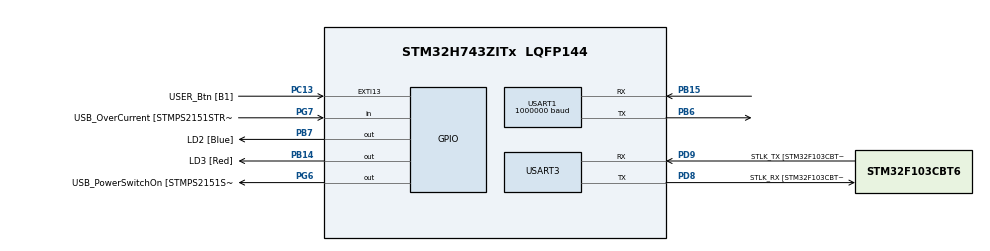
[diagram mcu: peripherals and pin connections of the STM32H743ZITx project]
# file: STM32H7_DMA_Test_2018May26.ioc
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Dma.Request0=USART1_TX
Dma.Request1=USART3_TX
Dma.USART1_TX.0.Direction=DMA_MEMORY_TO_PERIPH
Dma.USART1_TX.0.EventEnable=DISABLE
Dma.USART1_TX.0.FIFOMode=DMA_FIFOMODE_DISABLE
Dma.USART1_TX.0.Instance=DMA1_Stream0
Dma.USART1_TX.0.MemDataAlignment=DMA_MDATAALIGN_BYTE
Dma.USART1_TX.0.MemInc=DMA_MINC_ENABLE
Dma.USART1_TX.0.Mode=DMA_NORMAL
Dma.USART1_TX.0.PeriphDataAlignment=DMA_PDATAALIGN_BYTE
Dma.USART1_TX.0.PeriphInc=DMA_PINC_DISABLE
Dma.USART1_TX.0.Polarity=HAL_DMAMUX_REQ_GEN_RISING
Dma.USART1_TX.0.Priority=DMA_PRIORITY_LOW
Dma.USART1_TX.0.RequestNumber=1
Dma.USART1_TX.0.SyncEnable=DISABLE
Dma.USART1_TX.0.SyncPolarity=HAL_DMAMUX_SYNC_NO_EVENT
Dma.USART1_TX.0.SyncRequestNumber=1
Dma.USART3_TX.1.Direction=DMA_MEMORY_TO_PERIPH
Dma.USART3_TX.1.EventEnable=DISABLE
Dma.USART3_TX.1.FIFOMode=DMA_FIFOMODE_DISABLE
Dma.USART3_TX.1.Instance=DMA2_Stream1
Dma.USART3_TX.1.MemDataAlignment=DMA_MDATAALIGN_BYTE
Dma.USART3_TX.1.MemInc=DMA_MINC_ENABLE
Dma.USART3_TX.1.Mode=DMA_NORMAL
Dma.USART3_TX.1.PeriphDataAlignment=DMA_PDATAALIGN_BYTE
Dma.USART3_TX.1.PeriphInc=DMA_PINC_DISABLE
Dma.USART3_TX.1.Polarity=HAL_DMAMUX_REQ_GEN_RISING
Dma.USART3_TX.1.Priority=DMA_PRIORITY_LOW
Dma.USART3_TX.1.RequestNumber=1
Dma.USART3_TX.1.SyncEnable=DISABLE
Dma.USART3_TX.1.SyncPolarity=HAL_DMAMUX_SYNC_NO_EVENT
Dma.USART3_TX.1.SyncRequestNumber=1
FREERTOS.BinarySemaphores01=semTx,Static,semTxControlBlock
FREERTOS.MEMORY_ALLOCATION=2
FREERTOS.Tasks01=defaultTask,0,128,StartDefaultTask,Default,NULL,Dynamic,NULL,NULL;txTask,1,128,StartTxTask,Default,NULL,Static,txTaskBuffer,txTaskControlBlock
Mcu.Family=STM32H7
Mcu.Name=STM32H743ZITx
Mcu.Package=LQFP144
NVIC.DMA1_Stream0_IRQn=true\:5\:0\:false\:false\:true\:true\:false
NVIC.DMA2_Stream1_IRQn=true\:0\:0\:false\:false\:true\:false\:false
NVIC.PriorityGroup=NVIC_PRIORITYGROUP_4
NVIC.TIM1_UP_IRQn=true\:0\:0\:false\:false\:true\:false\:false
NVIC.TimeBase=TIM1_UP_IRQn
NVIC.TimeBaseIP=TIM1
NVIC.USART1_IRQn=true\:5\:0\:false\:false\:true\:true\:true
NVIC.USART3_IRQn=true\:5\:0\:false\:false\:true\:true\:true
PA1.GPIO_Label=RMII_REF_CLK
PA1.Signal=ETH_REF_CLK
PA10.GPIO_Label=USB_ID
PA10.Signal=USB_OTG_FS_ID
PA11.GPIO_Label=USB_DM
PA11.Signal=USB_OTG_FS_DM
PA12.GPIO_Label=USB_DP
PA12.Signal=USB_OTG_FS_DP
PA13.GPIO_Label=TMS
PA13.Mode=Serial_Wire
PA13.Signal=SYS_JTMS-SWDIO
PA14.GPIO_Label=TCK
PA14.Mode=Serial_Wire
PA14.Signal=SYS_JTCK-SWCLK
PA2.GPIO_Label=RMII_MDIO
PA2.Signal=ETH_MDIO
PA7.GPIO_Label=RMII_CRS_DV
PA7.Signal=ETH_CRS_DV
PA8.GPIO_Label=USB_SOF [TP1]
PA8.Signal=USB_OTG_FS_SOF
PA9.GPIO_Label=USB_VBUS
PA9.Signal=USB_OTG_FS_VBUS
PB13.GPIO_Label=RMII_TXD1
PB13.Signal=ETH_TXD1
PB14.GPIO_Label=LD3 [Red]
PB14.Signal=GPIO_Output
PB15.Mode=Asynchronous
PB15.Signal=USART1_RX
PB3.GPIO_Label=SWO
PB3.Signal=SYS_JTDO-SWO
PB6.Mode=Asynchronous
PB6.Signal=USART1_TX
PB7.GPIO_Label=LD2 [Blue]
PB7.Signal=GPIO_Output
PC1.GPIO_Label=RMII_MDC
PC1.Signal=ETH_MDC
PC13.GPIO_Label=USER_Btn [B1]
PC13.Signal=GPXTI13
PC14-OSC32_IN.Mode=LSE-External-Oscillator
PC14-OSC32_IN.Signal=RCC_OSC32_IN
PC15-OSC32_OUT.Mode=LSE-External-Oscillator
PC15-OSC32_OUT.Signal=RCC_OSC32_OUT
PC4.GPIO_Label=RMII_RXD0
PC4.Signal=ETH_RXD0
PC5.GPIO_Label=RMII_RXD1
PC5.Signal=ETH_RXD1
PD8.GPIO_Label=STLK_RX [STM32F103CBT6_PA3]
PD8.Mode=Asynchronous
PD8.Signal=USART3_TX
PD9.GPIO_Label=STLK_TX [STM32F103CBT6_PA2]
PD9.Mode=Asynchronous
PD9.Signal=USART3_RX
PG11.GPIO_Label=RMII_TX_EN
PG11.Signal=ETH_TX_EN
PG13.GPIO_Label=RMII_TXD0
PG13.Signal=ETH_TXD0
PG6.GPIO_Label=USB_PowerSwitchOn [STMPS2151STR_EN]
PG6.Signal=GPIO_Output
PG7.GPIO_Label=USB_OverCurrent [STMPS2151STR_FAULT]
PG7.Signal=GPIO_Input
PH0-OSC_IN.GPIO_Label=MCO
PH0-OSC_IN.Mode=HSE-External-Clock-Source
PH0-OSC_IN.Signal=RCC_OSC_IN
PH1-OSC_OUT.Mode=HSE-External-Clock-Source
PH1-OSC_OUT.Signal=RCC_OSC_OUT
ProjectManager.HeapSize=0x200
ProjectManager.StackSize=0x400
ProjectManager.TargetToolchain=SW4STM32
RCC.48MHZClocksFreq_Value=24000000
RCC.ADCFreq_Value=16125000
RCC.AHBFreq_Value=216000000
RCC.APB1CLKDivider=RCC_HCLK_DIV4
RCC.APB1Freq_Value=96000000
RCC.APB1TimFreq_Value=108000000
RCC.APB2CLKDivider=RCC_HCLK_DIV2
RCC.APB2Freq_Value=96000000
RCC.APB2TimFreq_Value=216000000
RCC.APB3Freq_Value=96000000
RCC.APB4Freq_Value=96000000
RCC.CortexFreq_Value=96000000
RCC.DIVM1=1
RCC.DIVN1=24
RCC.DIVQ1=4
RCC.HCLKFreq_Value=96000000
RCC.HSE_VALUE=8000000
RCC.HSI_VALUE=64000000
RCC.PLLM=25
RCC.PLLMUL=RCC_PLL_MUL9
RCC.PLLN=432
RCC.PLLQ=9
RCC.PLLSourceVirtual=RCC_PLLSOURCE_HSE
RCC.PRESCALERUSB=RCC_USBCLKSOURCE_PLL_DIV1_5
RCC.SYSCLKFreq_VALUE=96000000
RCC.SYSCLKSource=RCC_SYSCLKSOURCE_PLLCLK
RCC.SYSCLKSourceVirtual=RCC_SYSCLKSOURCE_PLLCLK
RCC.USBFreq_Value=48000000
RCC.VCOOutputFreq_Value=432000000
USART1.BaudRate=1000000
USART1.VirtualMode-Asynchronous=VM_ASYNC
USART1.WordLength=WORDLENGTH_8B
USART3.FIFOMode=FIFOMODE_DISABLE
USART3.RXFIFOThreshold=RXFIFO_THRESHOLD_1QUARTERFULL
USART3.TXFIFOThreshold=TXFIFO_THRESHOLD_1QUARTERFULL
USART3.VirtualMode-Asynchronous=VM_ASYNC
USART3.WordLength=WORDLENGTH_8B
VP_FREERTOS_VS_ENABLE.Mode=Enabled
VP_SYS_VS_tim1.Mode=TIM1
board=NUCLEO-H743ZI

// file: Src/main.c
/**
  ******************************************************************************
  * @file           : main.c
  * @brief          : Main program body
  ******************************************************************************
  * This notice applies to any and all portions of this file
  * that are not between comment pairs USER CODE BEGIN and
  * USER CODE END. Other portions of this file, whether
  * inserted by the user or by software development tools
  * are owned by their respective copyright owners.
  *
  * Copyright (c) 2018 STMicroelectronics International N.V.
  * All rights reserved.
  *
  * Redistribution and use in source and binary forms, with or without
  * modification, are permitted, provided that the following conditions are met:
  *
  * 1. Redistribution of source code must retain the above copyright notice,
  *    this list of conditions and the following disclaimer.
  * 2. Redistributions in binary form must reproduce the above copyright notice,
  *    this list of conditions and the following disclaimer in the documentation
  *    and/or other materials provided with the distribution.
  * 3. Neither the name of STMicroelectronics nor the names of other
  *    contributors to this software may be used to endorse or promote products
  *    derived from this software without specific written permission.
  * 4. This software, including modifications and/or derivative works of this
  *    software, must execute solely and exclusively on microcontroller or
  *    microprocessor devices manufactured by or for STMicroelectronics.
  * 5. Redistribution and use of this software other than as permitted under
  *    this license is void and will automatically terminate your rights under
  *    this license.
  *
  * THIS SOFTWARE IS PROVIDED BY STMICROELECTRONICS AND CONTRIBUTORS "AS IS"
  * AND ANY EXPRESS, IMPLIED OR STATUTORY WARRANTIES, INCLUDING, BUT NOT
  * LIMITED TO, THE IMPLIED WARRANTIES OF MERCHANTABILITY, FITNESS FOR A
  * PARTICULAR PURPOSE AND NON-INFRINGEMENT OF THIRD PARTY INTELLECTUAL PROPERTY
  * RIGHTS ARE DISCLAIMED TO THE FULLEST EXTENT PERMITTED BY LAW. IN NO EVENT
  * SHALL STMICROELECTRONICS OR CONTRIBUTORS BE LIABLE FOR ANY DIRECT, INDIRECT,
  * INCIDENTAL, SPECIAL, EXEMPLARY, OR CONSEQUENTIAL DAMAGES (INCLUDING, BUT NOT
  * LIMITED TO, PROCUREMENT OF SUBSTITUTE GOODS OR SERVICES; LOSS OF USE, DATA,
  * OR PROFITS; OR BUSINESS INTERRUPTION) HOWEVER CAUSED AND ON ANY THEORY OF
  * LIABILITY, WHETHER IN CONTRACT, STRICT LIABILITY, OR TORT (INCLUDING
  * NEGLIGENCE OR OTHERWISE) ARISING IN ANY WAY OUT OF THE USE OF THIS SOFTWARE,
  * EVEN IF ADVISED OF THE POSSIBILITY OF SUCH DAMAGE.
  *
  ******************************************************************************
  */
#include "main.h"
#include "stm32h7xx_hal.h"
#include "cmsis_os.h"
#include "dma.h"
#include "usart.h"
#include "gpio.h"

/* USER CODE BEGIN PV */
/* Private variables ---------------------------------------------------------*/

/* USER CODE END PV */

void SystemClock_Config(void);
void MX_FREERTOS_Init(void);

/* USER CODE BEGIN PFP */
/* Private function prototypes -----------------------------------------------*/

/* USER CODE END PFP */

int main(void)
{

  /* MCU Configuration----------------------------------------------------------*/

  /* Reset of all peripherals, Initializes the Flash interface and the Systick. */
  HAL_Init();

  /* Configure the system clock */
  SystemClock_Config();

  /* Initialize all configured peripherals */
  MX_GPIO_Init();
  MX_DMA_Init();
  MX_USART3_UART_Init();
  MX_USART1_UART_Init();

  /* Call init function for freertos objects (in freertos.c) */
  MX_FREERTOS_Init();

  /* Start scheduler */
  osKernelStart();

  /* We should never get here as control is now taken by the scheduler */

  /* Infinite loop */
  while (1)
  {

  }

}

void SystemClock_Config(void)
{

  RCC_OscInitTypeDef RCC_OscInitStruct;
  RCC_ClkInitTypeDef RCC_ClkInitStruct;
  RCC_PeriphCLKInitTypeDef PeriphClkInitStruct;

    /**Supply configuration update enable
    */
  MODIFY_REG(PWR->CR3, PWR_CR3_SCUEN, 0);

    /**Configure the main internal regulator output voltage
    */
  __HAL_PWR_VOLTAGESCALING_CONFIG(PWR_REGULATOR_VOLTAGE_SCALE1);

  while ((PWR->D3CR & (PWR_D3CR_VOSRDY)) != PWR_D3CR_VOSRDY)
  {

  }
    /**Initializes the CPU, AHB and APB busses clocks
    */
  RCC_OscInitStruct.OscillatorType = RCC_OSCILLATORTYPE_HSE;
  RCC_OscInitStruct.HSEState = RCC_HSE_BYPASS;
  RCC_OscInitStruct.PLL.PLLState = RCC_PLL_ON;
  RCC_OscInitStruct.PLL.PLLSource = RCC_PLLSOURCE_HSE;
  RCC_OscInitStruct.PLL.PLLM = 1;
  RCC_OscInitStruct.PLL.PLLN = 24;
  RCC_OscInitStruct.PLL.PLLP = 2;
  RCC_OscInitStruct.PLL.PLLQ = 4;
  RCC_OscInitStruct.PLL.PLLR = 2;
  RCC_OscInitStruct.PLL.PLLRGE = RCC_PLL1VCIRANGE_3;
  RCC_OscInitStruct.PLL.PLLVCOSEL = RCC_PLL1VCOWIDE;
  RCC_OscInitStruct.PLL.PLLFRACN = 0;
  if (HAL_RCC_OscConfig(&RCC_OscInitStruct) != HAL_OK)
  {
    _Error_Handler(__FILE__, __LINE__);
  }

    /**Initializes the CPU, AHB and APB busses clocks
    */
  RCC_ClkInitStruct.ClockType = RCC_CLOCKTYPE_HCLK|RCC_CLOCKTYPE_SYSCLK
                              |RCC_CLOCKTYPE_PCLK1|RCC_CLOCKTYPE_PCLK2
                              |RCC_CLOCKTYPE_D3PCLK1|RCC_CLOCKTYPE_D1PCLK1;
  RCC_ClkInitStruct.SYSCLKSource = RCC_SYSCLKSOURCE_PLLCLK;
  RCC_ClkInitStruct.SYSCLKDivider = RCC_SYSCLK_DIV1;
  RCC_ClkInitStruct.AHBCLKDivider = RCC_HCLK_DIV1;
  RCC_ClkInitStruct.APB3CLKDivider = RCC_APB3_DIV1;
  RCC_ClkInitStruct.APB1CLKDivider = RCC_APB1_DIV1;
  RCC_ClkInitStruct.APB2CLKDivider = RCC_APB2_DIV1;
  RCC_ClkInitStruct.APB4CLKDivider = RCC_APB4_DIV1;

  if (HAL_RCC_ClockConfig(&RCC_ClkInitStruct, FLASH_LATENCY_1) != HAL_OK)
  {
    _Error_Handler(__FILE__, __LINE__);
  }

  PeriphClkInitStruct.PeriphClockSelection = RCC_PERIPHCLK_USART3|RCC_PERIPHCLK_USART1;
  PeriphClkInitStruct.Usart234578ClockSelection = RCC_USART234578CLKSOURCE_D2PCLK1;
  PeriphClkInitStruct.Usart16ClockSelection = RCC_USART16CLKSOURCE_D2PCLK2;
  if (HAL_RCCEx_PeriphCLKConfig(&PeriphClkInitStruct) != HAL_OK)
  {
    _Error_Handler(__FILE__, __LINE__);
  }

    /**Configure the Systick interrupt time
    */
  HAL_SYSTICK_Config(SystemCoreClock/1000);

    /**Configure the Systick
    */
  HAL_SYSTICK_CLKSourceConfig(SYSTICK_CLKSOURCE_HCLK);

  /* SysTick_IRQn interrupt configuration */
  HAL_NVIC_SetPriority(SysTick_IRQn, 15, 0);
}

void HAL_TIM_PeriodElapsedCallback(TIM_HandleTypeDef *htim)
{
  if (htim->Instance == TIM1) {
    HAL_IncTick();
  }
}

void _Error_Handler(char *file, int line)
{
  while(1)
  {
  }
}

/************************ (C) COPYRIGHT STMicroelectronics *****END OF FILE****/

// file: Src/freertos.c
/**
  ******************************************************************************
  * File Name          : freertos.c
  * Description        : Code for freertos applications
  ******************************************************************************
  * This notice applies to any and all portions of this file
  * that are not between comment pairs USER CODE BEGIN and
  * USER CODE END. Other portions of this file, whether
  * inserted by the user or by software development tools
  * are owned by their respective copyright owners.
  *
  * Copyright (c) 2018 STMicroelectronics International N.V.
  * All rights reserved.
  *
  * Redistribution and use in source and binary forms, with or without
  * modification, are permitted, provided that the following conditions are met:
  *
  * 1. Redistribution of source code must retain the above copyright notice,
  *    this list of conditions and the following disclaimer.
  * 2. Redistributions in binary form must reproduce the above copyright notice,
  *    this list of conditions and the following disclaimer in the documentation
  *    and/or other materials provided with the distribution.
  * 3. Neither the name of STMicroelectronics nor the names of other
  *    contributors to this software may be used to endorse or promote products
  *    derived from this software without specific written permission.
  * 4. This software, including modifications and/or derivative works of this
  *    software, must execute solely and exclusively on microcontroller or
  *    microprocessor devices manufactured by or for STMicroelectronics.
  * 5. Redistribution and use of this software other than as permitted under
  *    this license is void and will automatically terminate your rights under
  *    this license.
  *
  * THIS SOFTWARE IS PROVIDED BY STMICROELECTRONICS AND CONTRIBUTORS "AS IS"
  * AND ANY EXPRESS, IMPLIED OR STATUTORY WARRANTIES, INCLUDING, BUT NOT
  * LIMITED TO, THE IMPLIED WARRANTIES OF MERCHANTABILITY, FITNESS FOR A
  * PARTICULAR PURPOSE AND NON-INFRINGEMENT OF THIRD PARTY INTELLECTUAL PROPERTY
  * RIGHTS ARE DISCLAIMED TO THE FULLEST EXTENT PERMITTED BY LAW. IN NO EVENT
  * SHALL STMICROELECTRONICS OR CONTRIBUTORS BE LIABLE FOR ANY DIRECT, INDIRECT,
  * INCIDENTAL, SPECIAL, EXEMPLARY, OR CONSEQUENTIAL DAMAGES (INCLUDING, BUT NOT
  * LIMITED TO, PROCUREMENT OF SUBSTITUTE GOODS OR SERVICES; LOSS OF USE, DATA,
  * OR PROFITS; OR BUSINESS INTERRUPTION) HOWEVER CAUSED AND ON ANY THEORY OF
  * LIABILITY, WHETHER IN CONTRACT, STRICT LIABILITY, OR TORT (INCLUDING
  * NEGLIGENCE OR OTHERWISE) ARISING IN ANY WAY OUT OF THE USE OF THIS SOFTWARE,
  * EVEN IF ADVISED OF THE POSSIBILITY OF SUCH DAMAGE.
  *
  ******************************************************************************
  */

#include "FreeRTOS.h"
#include "task.h"
#include "cmsis_os.h"

/* USER CODE BEGIN Includes */
#include "gpio.h"
#include "usart.h"
/* USER CODE END Includes */

osThreadId defaultTaskHandle;
osThreadId txTaskHandle;
uint32_t txTaskBuffer[ 128 ];
osStaticThreadDef_t txTaskControlBlock;
osSemaphoreId semTxHandle;
osStaticSemaphoreDef_t semTxControlBlock;

void StartDefaultTask(void const * argument);
void StartTxTask(void const * argument);

void MX_FREERTOS_Init(void); /* (MISRA C 2004 rule 8.1) */

/* GetIdleTaskMemory prototype (linked to static allocation support) */
void vApplicationGetIdleTaskMemory( StaticTask_t **ppxIdleTaskTCBBuffer, StackType_t **ppxIdleTaskStackBuffer, uint32_t *pulIdleTaskStackSize );

/* Hook prototypes */

/* USER CODE BEGIN GET_IDLE_TASK_MEMORY */
static StaticTask_t xIdleTaskTCBBuffer;
static StackType_t xIdleStack[configMINIMAL_STACK_SIZE];

void vApplicationGetIdleTaskMemory( StaticTask_t **ppxIdleTaskTCBBuffer, StackType_t **ppxIdleTaskStackBuffer, uint32_t *pulIdleTaskStackSize )
{
  *ppxIdleTaskTCBBuffer = &xIdleTaskTCBBuffer;
  *ppxIdleTaskStackBuffer = &xIdleStack[0];
  *pulIdleTaskStackSize = configMINIMAL_STACK_SIZE;
  /* place for user code */
}
/* USER CODE END GET_IDLE_TASK_MEMORY */

/* Init FreeRTOS */

void MX_FREERTOS_Init(void) {

  /* Create the semaphores(s) */
  /* definition and creation of semTx */
  osSemaphoreStaticDef(semTx, &semTxControlBlock);
  semTxHandle = osSemaphoreCreate(osSemaphore(semTx), 1);

  /* Create the thread(s) */
  /* definition and creation of defaultTask */
  osThreadDef(defaultTask, StartDefaultTask, osPriorityNormal, 0, 128);
  defaultTaskHandle = osThreadCreate(osThread(defaultTask), NULL);

  /* definition and creation of txTask */
  osThreadStaticDef(txTask, StartTxTask, osPriorityAboveNormal, 0, 128, txTaskBuffer, &txTaskControlBlock);
  txTaskHandle = osThreadCreate(osThread(txTask), NULL);

}

/* StartDefaultTask function */
void StartDefaultTask(void const * argument)
{

  /* USER CODE BEGIN StartDefaultTask */
  /* Infinite loop */
  for(;;)
  {
	HAL_GPIO_TogglePin(GPIOB, GPIO_PIN_14);
    osDelay(500);
  }
  /* USER CODE END StartDefaultTask */
}

/* StartTxTask function */
void StartTxTask(void const * argument)
{
  /* USER CODE BEGIN StartTxTask */
  char myMessage[] = "Hello World";

  /* Infinite loop */
  for(;;)
  {
	  HAL_UART_Transmit_DMA(&huart3, (uint8_t*)myMessage, sizeof(myMessage));
	  xSemaphoreTake(semTxHandle, portMAX_DELAY);

	  vTaskDelay(100);
  }
  /* USER CODE END StartTxTask */
}

/* USER CODE BEGIN Application */
void HAL_UART_TxCpltCallback(UART_HandleTypeDef *huart)
{
	if(huart == &huart3){
		BaseType_t xHigherPriorityTaskWoken = pdTRUE;
		xSemaphoreGiveFromISR(semTxHandle, &xHigherPriorityTaskWoken);
	}
}
/* USER CODE END Application */

/************************ (C) COPYRIGHT STMicroelectronics *****END OF FILE****/
